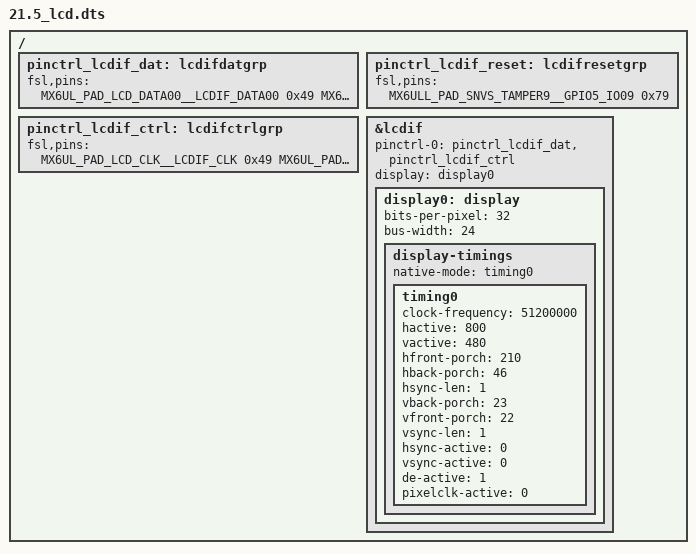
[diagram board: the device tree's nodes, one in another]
/ {
    pinctrl_lcdif_dat: lcdifdatgrp {
                fsl,pins = <
                    MX6UL_PAD_LCD_DATA00__LCDIF_DATA00  0x49
                    MX6UL_PAD_LCD_DATA01__LCDIF_DATA01  0x49
                    MX6UL_PAD_LCD_DATA02__LCDIF_DATA02  0x49
                    MX6UL_PAD_LCD_DATA03__LCDIF_DATA03  0x49
                    MX6UL_PAD_LCD_DATA04__LCDIF_DATA04  0x49
                    MX6UL_PAD_LCD_DATA05__LCDIF_DATA05  0x49
                    MX6UL_PAD_LCD_DATA06__LCDIF_DATA06  0x49
                    MX6UL_PAD_LCD_DATA07__LCDIF_DATA07  0x49
                    MX6UL_PAD_LCD_DATA08__LCDIF_DATA08  0x49
                    MX6UL_PAD_LCD_DATA09__LCDIF_DATA09  0x49
                    MX6UL_PAD_LCD_DATA10__LCDIF_DATA10  0x49
                    MX6UL_PAD_LCD_DATA11__LCDIF_DATA11  0x49
                    MX6UL_PAD_LCD_DATA12__LCDIF_DATA12  0x49
                    MX6UL_PAD_LCD_DATA13__LCDIF_DATA13  0x49
                    MX6UL_PAD_LCD_DATA14__LCDIF_DATA14  0x49
                    MX6UL_PAD_LCD_DATA15__LCDIF_DATA15  0x49
                    MX6UL_PAD_LCD_DATA16__LCDIF_DATA16  0x49
                    MX6UL_PAD_LCD_DATA17__LCDIF_DATA17  0x49
                    MX6UL_PAD_LCD_DATA18__LCDIF_DATA18  0x49
                    MX6UL_PAD_LCD_DATA19__LCDIF_DATA19  0x49
                    MX6UL_PAD_LCD_DATA20__LCDIF_DATA20  0x49
                    MX6UL_PAD_LCD_DATA21__LCDIF_DATA21  0x49
                    MX6UL_PAD_LCD_DATA22__LCDIF_DATA22  0x49
                    MX6UL_PAD_LCD_DATA23__LCDIF_DATA23  0x49
                >;
            };

            pinctrl_lcdif_ctrl: lcdifctrlgrp {
                fsl,pins = <
                    MX6UL_PAD_LCD_CLK__LCDIF_CLK	    0x49
                    MX6UL_PAD_LCD_ENABLE__LCDIF_ENABLE  0x49
                    MX6UL_PAD_LCD_HSYNC__LCDIF_HSYNC    0x49
                    MX6UL_PAD_LCD_VSYNC__LCDIF_VSYNC    0x49
                >;
            };

            pinctrl_lcdif_reset: lcdifresetgrp {
                            fsl,pins = <
                                    /* used for lcd reset */
                                    MX6ULL_PAD_SNVS_TAMPER9__GPIO5_IO09  0x79
                            >;
                    };

    &lcdif {
        pinctrl-names = "default";
        pinctrl-0 = <&pinctrl_lcdif_dat
                &pinctrl_lcdif_ctrl>;
                // &pinctrl_lcdif_reset>;
        display = <&display0>;
        status = "okay";

        display0: display {
            bits-per-pixel = <32>;
            bus-width = <24>;

            display-timings {
                native-mode = <&timing0>;
                timing0: timing0 {
                clock-frequency = <51200000>;
                hactive = <800>;
                vactive = <480>;
                hfront-porch = <210>;
                hback-porch = <46>;
                hsync-len = <1>;
                vback-porch = <23>;
                vfront-porch = <22>;
                vsync-len = <1>;

                hsync-active = <0>;
                vsync-active = <0>;
                de-active = <1>;
                pixelclk-active = <0>;
                };
            };
        };
    };
};
